VERSION ""

NS_ :

BS_:

BU_: ADTF

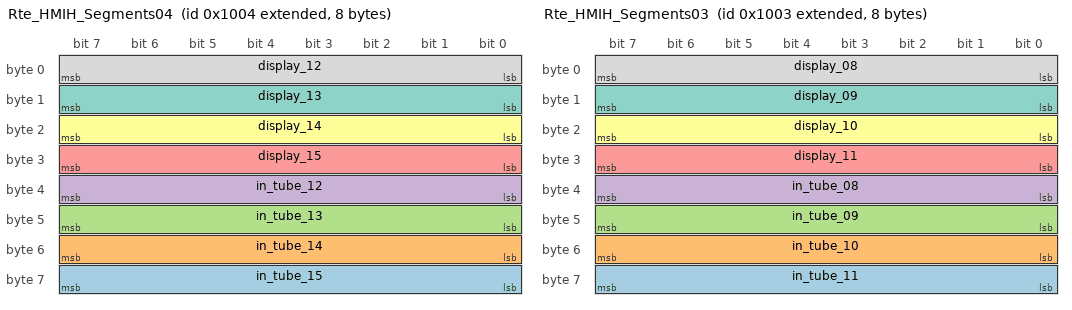
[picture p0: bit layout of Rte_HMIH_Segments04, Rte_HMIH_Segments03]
BO_ 2147487748 Rte_HMIH_Segments04: 8 ADTF
 SG_ in_tube_15 : 56|8@1+ (1,0) [0|0] "" Vector__XXX
 SG_ in_tube_14 : 48|8@1+ (1,0) [0|0] "" Vector__XXX
 SG_ in_tube_13 : 40|8@1+ (1,0) [0|0] "" Vector__XXX
 SG_ in_tube_12 : 32|8@1+ (1,0) [0|0] "" Vector__XXX
 SG_ display_15 : 24|8@1+ (1,0) [0|255] "" Vector__XXX
 SG_ display_14 : 16|8@1+ (1,0) [0|255] "" Vector__XXX
 SG_ display_13 : 8|8@1+ (1,0) [0|255] "" Vector__XXX
 SG_ display_12 : 0|8@1+ (1,0) [0|255] "" Vector__XXX

BO_ 2147487747 Rte_HMIH_Segments03: 8 ADTF
 SG_ in_tube_11 : 56|8@1+ (1,0) [0|0] "" Vector__XXX
 SG_ in_tube_10 : 48|8@1+ (1,0) [0|0] "" Vector__XXX
 SG_ in_tube_09 : 40|8@1+ (1,0) [0|0] "" Vector__XXX
 SG_ in_tube_08 : 32|8@1+ (1,0) [0|0] "" Vector__XXX
 SG_ display_11 : 24|8@1+ (1,0) [0|255] "" Vector__XXX
 SG_ display_10 : 16|8@1+ (1,0) [0|255] "" Vector__XXX
 SG_ display_09 : 8|8@1+ (1,0) [0|255] "" Vector__XXX
 SG_ display_08 : 0|8@1+ (1,0) [0|255] "" Vector__XXX

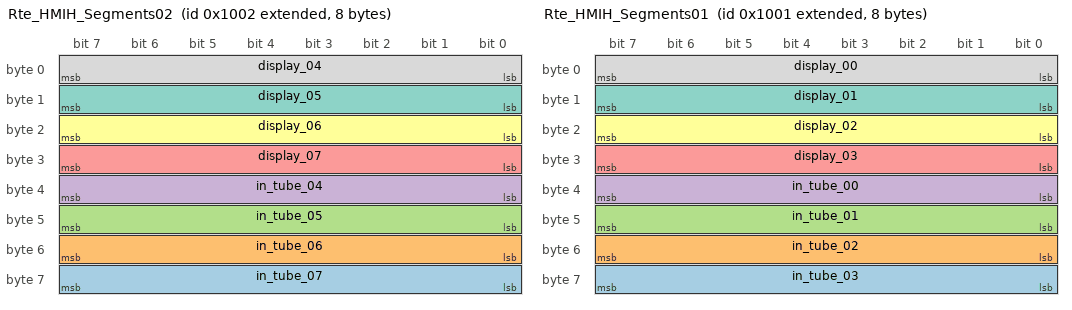
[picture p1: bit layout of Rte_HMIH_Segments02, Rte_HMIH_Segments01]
BO_ 2147487746 Rte_HMIH_Segments02: 8 ADTF
 SG_ in_tube_07 : 56|8@1+ (1,0) [0|0] "" Vector__XXX
 SG_ in_tube_06 : 48|8@1+ (1,0) [0|0] "" Vector__XXX
 SG_ in_tube_05 : 40|8@1+ (1,0) [0|0] "" Vector__XXX
 SG_ in_tube_04 : 32|8@1+ (1,0) [0|0] "" Vector__XXX
 SG_ display_07 : 24|8@1+ (1,0) [0|255] "" Vector__XXX
 SG_ display_06 : 16|8@1+ (1,0) [0|255] "" Vector__XXX
 SG_ display_05 : 8|8@1+ (1,0) [0|255] "" Vector__XXX
 SG_ display_04 : 0|8@1+ (1,0) [0|255] "" Vector__XXX

BO_ 2147487745 Rte_HMIH_Segments01: 8 ADTF
 SG_ in_tube_03 : 56|8@1+ (1,0) [0|0] "" Vector__XXX
 SG_ in_tube_02 : 48|8@1+ (1,0) [0|0] "" Vector__XXX
 SG_ in_tube_01 : 40|8@1+ (1,0) [0|0] "" Vector__XXX
 SG_ in_tube_00 : 32|8@1+ (1,0) [0|0] "" Vector__XXX
 SG_ display_03 : 24|8@1+ (1,0) [0|255] "" Vector__XXX
 SG_ display_02 : 16|8@1+ (1,0) [0|255] "" Vector__XXX
 SG_ display_01 : 8|8@1+ (1,0) [0|255] "" Vector__XXX
 SG_ display_00 : 0|8@1+ (1,0) [0|255] "" Vector__XXX

SIG_GROUP_ 2147487745 Rte_HMIH_Segmets 1 :;
